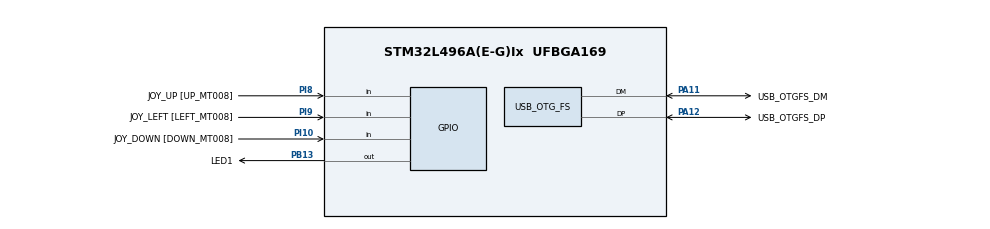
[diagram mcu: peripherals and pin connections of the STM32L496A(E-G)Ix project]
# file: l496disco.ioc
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Mcu.Family=STM32L4
Mcu.Name=STM32L496A(E-G)Ix
Mcu.Package=UFBGA169
NVIC.OTG_FS_IRQn=true\:0\:0\:false\:false\:true\:false\:true\:true
NVIC.PriorityGroup=NVIC_PRIORITYGROUP_4
PA10.GPIO_Label=USB_OTGFS_ID
PA10.Signal=USB_OTG_FS_ID
PA11.GPIO_Label=USB_OTGFS_DM
PA11.Mode=Device_Only
PA11.Signal=USB_OTG_FS_DM
PA12.GPIO_Label=USB_OTGFS_DP
PA12.Mode=Device_Only
PA12.Signal=USB_OTG_FS_DP
PA13\ (JTMS/SWDIO).GPIO_Label=SWDIO
PA13\ (JTMS/SWDIO).Mode=Serial_Wire
PA13\ (JTMS/SWDIO).Signal=SYS_JTMS-SWDIO
PA14\ (JTCK/SWCLK).GPIO_Label=SWCLK
PA14\ (JTCK/SWCLK).Mode=Serial_Wire
PA14\ (JTCK/SWCLK).Signal=SYS_JTCK-SWCLK
PA9.GPIO_Label=USB_OTGFS_VBUS
PA9.Signal=USB_OTG_FS_VBUS
PB13.GPIO_Label=LED1
PB13.GPIO_ModeDefaultOutputPP=GPIO_MODE_OUTPUT_OD
PB13.GPIO_PuPd=GPIO_NOPULL
PB13.Signal=GPIO_Output
PB3\ (JTDO/TRACESWO).GPIO_Label=SWO
PB3\ (JTDO/TRACESWO).Signal=SYS_JTDO-SWO
PC14-OSC32_IN\ (PC14).Mode=LSE-External-Oscillator
PC14-OSC32_IN\ (PC14).Signal=RCC_OSC32_IN
PC15-OSC32_OUT\ (PC15).Mode=LSE-External-Oscillator
PC15-OSC32_OUT\ (PC15).Signal=RCC_OSC32_OUT
PI10.GPIO_Label=JOY_DOWN [DOWN_MT008]
PI10.GPIO_PuPd=GPIO_PULLDOWN
PI10.Signal=GPIO_Input
PI8.GPIO_Label=JOY_UP [UP_MT008]
PI8.GPIO_PuPd=GPIO_PULLDOWN
PI8.Signal=GPIO_Input
PI9.GPIO_Label=JOY_LEFT [LEFT_MT008]
PI9.GPIO_PuPd=GPIO_PULLDOWN
PI9.Signal=GPIO_Input
ProjectManager.HeapSize=0x200
ProjectManager.StackSize=0x400
ProjectManager.TargetToolchain=CMake
RCC.ADCFreq_Value=48000000
RCC.AHBFreq_Value=80000000
RCC.APB1Freq_Value=80000000
RCC.APB1TimFreq_Value=80000000
RCC.APB2Freq_Value=80000000
RCC.APB2TimFreq_Value=80000000
RCC.CortexFreq_Value=80000000
RCC.HCLKFreq_Value=80000000
RCC.HSE_VALUE=8000000
RCC.HSI48_VALUE=48000000
RCC.HSI_VALUE=16000000
RCC.MSI_VALUE=4000000
RCC.PLLN=40
RCC.PLLSAI1N=24
RCC.SYSCLKFreq_VALUE=80000000
RCC.SYSCLKSource=RCC_SYSCLKSOURCE_PLLCLK
RCC.USBFreq_Value=48000000
RCC.VCOOutputFreq_Value=160000000
USB_DEVICE.CLASS_NAME_FS=CDC
USB_DEVICE.VirtualMode=Cdc
USB_DEVICE.VirtualModeFS=Cdc_FS
USB_OTG_FS.VirtualMode=Device_Only
VP_USB_DEVICE_VS_USB_DEVICE_CDC_FS.Mode=CDC_FS
board=custom

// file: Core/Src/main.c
/* USER CODE BEGIN Header */
/**
  ******************************************************************************
  * @file           : main.c
  * @brief          : Main program body
  ******************************************************************************
  * @attention
  *
  * Copyright (c) 2025 STMicroelectronics.
  * All rights reserved.
  *
  * This software is licensed under terms that can be found in the LICENSE file
  * in the root directory of this software component.
  * If no LICENSE file comes with this software, it is provided AS-IS.
  *
  ******************************************************************************
  */
/* USER CODE END Header */
#include "main.h"
#include "gpio.h"

/* USER CODE BEGIN Includes */
#include "main.hpp"
/* USER CODE END Includes */

void SystemClock_Config(void);

int main(void)
{

  /* MCU Configuration--------------------------------------------------------*/

  /* Reset of all peripherals, Initializes the Flash interface and the Systick. */
  LL_APB2_GRP1_EnableClock(LL_APB2_GRP1_PERIPH_SYSCFG);
  LL_APB1_GRP1_EnableClock(LL_APB1_GRP1_PERIPH_PWR);

  /* System interrupt init*/
  NVIC_SetPriorityGrouping(NVIC_PRIORITYGROUP_4);

  /* SysTick_IRQn interrupt configuration */
  NVIC_SetPriority(SysTick_IRQn, NVIC_EncodePriority(NVIC_GetPriorityGrouping(),15, 0));

  /* Configure the system clock */
  SystemClock_Config();

  /* Initialize all configured peripherals */
  MX_GPIO_Init();

  /* Infinite loop */
  /* USER CODE BEGIN WHILE */
  setup();
  while (1)
  {
    /* USER CODE END WHILE */
    loop();
  }
}

void SystemClock_Config(void)
{
  LL_FLASH_SetLatency(LL_FLASH_LATENCY_0);
  while(LL_FLASH_GetLatency()!= LL_FLASH_LATENCY_0)
  {
  }
  LL_PWR_SetRegulVoltageScaling(LL_PWR_REGU_VOLTAGE_SCALE1);
  while (LL_PWR_IsActiveFlag_VOS() != 0)
  {
  }
  LL_RCC_MSI_Enable();

   /* Wait till MSI is ready */
  while(LL_RCC_MSI_IsReady() != 1)
  {

  }
  LL_RCC_MSI_EnableRangeSelection();
  LL_RCC_MSI_SetRange(LL_RCC_MSIRANGE_6);
  LL_RCC_MSI_SetCalibTrimming(0);
  LL_RCC_SetSysClkSource(LL_RCC_SYS_CLKSOURCE_MSI);

   /* Wait till System clock is ready */
  while(LL_RCC_GetSysClkSource() != LL_RCC_SYS_CLKSOURCE_STATUS_MSI)
  {

  }
  LL_RCC_SetAHBPrescaler(LL_RCC_SYSCLK_DIV_1);
  LL_RCC_SetAPB1Prescaler(LL_RCC_APB1_DIV_1);
  LL_RCC_SetAPB2Prescaler(LL_RCC_APB2_DIV_1);

  LL_Init1msTick(4000000);

  LL_SetSystemCoreClock(4000000);
}

void Error_Handler(void)
{
  __disable_irq();
  while (1)
  {
  }
}
